# ISP_CSI2C_REGS1 register map
Vendor: Texas Instruments
Peripheral module from a debugger description file (folder omap36xx).
Registers are 32-bit, access per field, reset 0x0 unless marked. A register's access mark holds for its fields unless they carry their own. Offsets are as the file gives them; lines under a group give offsets from that group; [hi:lo] are bit positions; {n}, {i} and the like mark numbered series; 'fields as' and 'values as' point back to an identical list; <NAME> marks a mode.

## ISP_CSI2C_REGS1
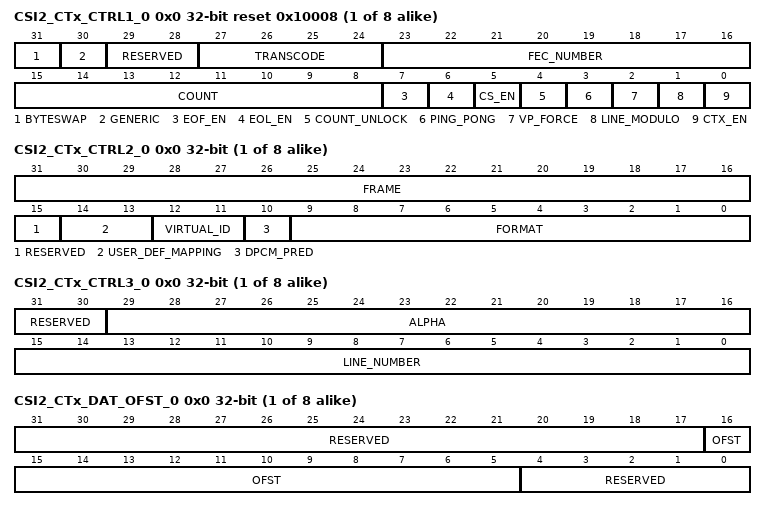
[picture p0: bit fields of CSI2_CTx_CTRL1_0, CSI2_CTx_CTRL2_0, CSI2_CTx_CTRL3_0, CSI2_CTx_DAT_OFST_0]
{0x0+0x20*i} CSI2_CTx_CTRL1_{i} reset 0x10008 (i=0..7) — CONTROL REGISTER - Context This register controls the Context. This register is shadowed: modifications are taken into account after the next FSC sync code.
  [31] BYTESWAP rw — Allows swapping bytes two by two in the payload data.It doesn't affect - short packets- long packet header or footers- CRC calculationThe purpose is to by swap data send to the Interconnect port and/or video port
    0=Disabled; 1=Enabled
  [30] GENERIC rw — Enables the generic mode.
    0=Disabled.Data is received according to CSI2_CTX_CTRL1.FORMAT andthe long packet code transmitted in the MIPI stream is used; 1=Enabled.Data is received according to CSI2_CTX_CTRL1.FORMAT andthe long packet code transmitted in the MIPI stream is ignored
  [29:28] RESERVED ro — Write 0s for future compatibility. Read returns 0.
  [27:24] TRANSCODE rw — Enables image transcoding.When this features is enabled:- the data format from the camera is defined by the FORMAT register- the format after transcode is defined by the TRANSCODE register. The memory storage / video port formats is defined by the TRANSCODE register
    0=Feature disabled; 1=Outputs DPCM compressed RAW10 data.After compression, pixels are coded on 8 bits.Data in memory is organized as regular RAW8 data; 2=Outputs DPCM compressed RAW12 data.After compression, pixels are coded on 8 bits.Data in memory is organized as regular RAW8 data; 3=Outputs ALAW compressed RAW10 data.After compression, pixels are coded on 8 bits.Data in memory is organized as regular RAW8 data; 4=Outputs uncompressed RAW8 data.Data in memory is organized as regular RAW8 data; 5=Outputs uncompressed RAW10 data.Data in memory is organized as regular RAW10+EXP16 data; 6=Outputs uncompressed RAW10 data.Data in memory is organized as regular packed RAW10 data; 7=Outputs uncompressed RAW12 data.Data in memory is organized as regular RAW12+EXP16 data; 8=Outputs uncompressed RAW12 data.Data in memory is organized as regular packed RAW12 data; 9=Outputs uncompressed RAW14 data
  [23:16] FEC_NUMBER rw — Number of FEC to receive between using swap of CSI2_CTX_DAT_PING_ADDR and CSI2_CTX_DAT_PONG_ADDR for the calculation of the address in memory. (shall be used only in interlace mode, otherwise set to '1')
  [15:8] COUNT rw — Sets the number of frame to acquire. Once the frame acquisition starts, the COUNT value is decremented after every frame. When COUNT reaches 0, the FRAME_NUMBER_IRQ interrupt is triggered and CTX_EN is set to '0'. Writes to this bit field are controlled by the COUNT_UNLOCK bit. During the same Interconnect write access , the bit-field COUNT_UNLOCK shall be written in addition to COUNT bit-field in order to change the COUNT value. COUNT can be overwritten dynamically with a new count value.' 0: Infinite number of frames (no count).1: 1 frame to acquire...255: 255 frames to acquire.
  [7] EOF_EN rw — Indicates if the end of frame signal shall be asserted at the end of the line.
    0=EOF_EN_0_r (The end of frame signal is not asserted at the end of each frame.); 1=EOF_EN_1_r (The end of frame signal is asserted at the end of each frame.)
  [6] EOL_EN rw — Indicates if the end of line signal shall be asserted at the end of the line.
    0=EOL_EN_0_r (The end of line signal is not asserted at the end of each frame.); 1=EOL_EN_1_r (The end of line signal is asserted at the end of each frame.)
  [5] CS_EN rw — Enables the checksum check for the received payload (long packet only).
    0=Disabled; 1=Enabled
  [4] COUNT_UNLOCK wo — Unlock writes to the COUNT bit field.
    0=COUNT_UNLOCK_0_w (COUNT bit field is locked. Writes have no effect); 1=COUNT_UNLOCK_1_w (COUNT bit field is unlocked. Writes are possible.)
  [3] PING_PONG ro — Indicates whether the PING or PONG destination address (CSI2_CTX_DAT_PING_ADDR or CSI2_CTX_DAT_PONG_ADDR) was used to write the last frame.This bit field toggles after every FEC_NUMBER FEC sync code received for the current context.
    0=PING_PONG_0_r (PING buffer); 1=PING_PONG_1_r (PONG buffer)
  [2] VP_FORCE rw — Forces sending of the data to both VPORT and Interconnect.Only applies to formats that existing in 2 versions:- one sending data to Interconnect port only- one sending data to VPORTonly (tagged with the +VP extension) The format version sending data only to Interconnect should be choosen.
    0=Disabled; 1=Enabled
  [1] LINE_MODULO rw — Line modulo configuration
    0=CSI2_CTX_CTRL3.LINE_NUMBER is used once per frame for the generation of the LINE_NUMBER_IRQ; 1=CSI2_CTX_CTRL3.LINE_NUMBER is used as a modulo number for the generation of the LINE_NUMBER_IRQ (multiple times the interrupt can be generated for each frame)
  [0] CTX_EN rw — Enables the Context
    0=Disabled; 1=Enabled
{0x0+0x20*i} CSI2_CTx_CTRL2_{i} (i=0..7) — CONTROL REGISTER - Context This register controls the Context. This register is shadowed: modifications are taken into account after the next FSC sync code (except for VIRTUAL_ID and FORMAT fields). The change of VIRTUIAL_ID and FORMAT has to occur only when the context is disabled (CSI2_CTX_CTRL1.CTX_EN).
  [31:16] FRAME ro — Frame number received
  [15] RESERVED ro — Write 0s for future compatibility. Read returns 0.
  [14:13] USER_DEF_MAPPING rw — Selects the pixel format of USER_DEFINED in FORMAT
    0=RAW6; 1=RAW7; 2=RAW8 (not valid if FORMAT is USER_DEFINED_8_BIT_DATA_TYPE_x_EXP8 with x from 1 to 8)
  [12:11] VIRTUAL_ID rw — Virtual channel ID
    {v}=Virtual Channel ID {v} (v=0..3)
  [10] DPCM_PRED rw — Selects the DPCM predictor.
    0=The advanced predictor is used.Not supported for 10 - 8 - 10 algorithm.Performance limited to 1 pixel/cycle; 1=The simple predictor is used
  [9:0] FORMAT rw — Data format selection.
    0=OTHERS (except NULL and BLANKING packets); 18=Embedded 8-bit non-image data (e.g. JPEG); 24=YUV420 8bit; 25=YUV420 10bit; 26=YUV420 8bit legacy; 28=YUV420 8bit + CSPS; 29=YUV420 10bit + CSPS; 30=YUV422 8bit; 31=YUV422 10bit; 34=RGB565; 36=RGB888; 40=RAW6; 41=RAW7; 42=RAW8; 43=RAW10; 44=RAW12; 45=RAW14; 51=RGB666 + EXP32_24; {v}=USER_DEFINED_8_BIT_DATA_TYPE_{v-63} (v=64..71); 104=RAW6 + EXP8; 105=RAW7 + EXP8; {v}=USER_DEFINED_8_BIT_DATA_TYPE_{v-127} + EXP8 (v=128..135); 158=YUV422 8bit + VP; 160=RGB444 + EXP16; 161=RGB555 + EXP16; 171=RAW10 + EXP16; 172=RAW12 + EXP16; 173=RAW14 + EXP16; 222=Same as YUV422 8bit + VP but datais send as 16-bit wide words to video port.Could be used together with the GENERIC and BYTESWAP features; 227=RGB666 + EXP32; 228=RGB888 + EXP32; 232=RAW6 + DPCM10 + VP; 0x12A=RAW8 + VP; 0x12C=RAW12 + VP; 0x12D=RAW14 + VP; 0x12F=RAW10 + VP; 0x140=USER_DEFINED_8_BIT_DATA_TYPE_1_DPCM12_VP; 0x141=USER_DEFINED_8_BIT_DATA_TYPE_2_DPCM12_VP; 0x142=USER_DEFINED_8_BIT_DATA_TYPE_3_DPCM12_VP; 0x143=USER_DEFINED_8_BIT_DATA_TYPE_4_DPCM12_VP; 0x144=USER_DEFINED_8_BIT_DATA_TYPE_5_DPCM12_VP; 0x145=USER_DEFINED_8_BIT_DATA_TYPE_6_DPCM12_VP; 0x146=USER_DEFINED_8_BIT_DATA_TYPE_7_DPCM12_VP; 0x147=USER_DEFINED_8_BIT_DATA_TYPE_8_DPCM12_VP; 0x1C0=USER_DEFINED_8_BIT_DATA_TYPE_1_DPCM12_EXP16; 0x1C1=USER_DEFINED_8_BIT_DATA_TYPE_2_DPCM12_EXP16; 0x1C2=USER_DEFINED_8_BIT_DATA_TYPE_3_DPCM12_EXP16; 0x1C3=USER_DEFINED_8_BIT_DATA_TYPE_4_DPCM12_EXP16; 0x1C4=USER_DEFINED_8_BIT_DATA_TYPE_5_DPCM12_EXP16; 0x1C5=USER_DEFINED_8_BIT_DATA_TYPE_6_DPCM12_EXP16; 0x1C6=USER_DEFINED_8_BIT_DATA_TYPE_7_DPCM12_EXP16; 0x1C7=USER_DEFINED_8_BIT_DATA_TYPE_8_DPCM12_EXP16; 0x229=RAW7 + DPCM10 + EXP16; 0x2A8=RAW6 + DPCM10 + EXP16; 0x2AA=RAW8 + DPCM10 + EXP16; 0x2C0=USER_DEFINED_8_BIT_DATA_TYPE_1 + DPCM10 + EXP16; 0x2C1=USER_DEFINED_8_BIT_DATA_TYPE_2 + DPCM10 + EXP16; 0x2C2=USER_DEFINED_8_BIT_DATA_TYPE_3 + DPCM10 + EXP16; 0x2C3=USER_DEFINED_8_BIT_DATA_TYPE_4 + DPCM10 + EXP16; 0x2C4=USER_DEFINED_8_BIT_DATA_TYPE_5 + DPCM10 + EXP16; 0x2C5=USER_DEFINED_8_BIT_DATA_TYPE_6 + DPCM10 + EXP16; 0x2C6=USER_DEFINED_8_BIT_DATA_TYPE_7 + DPCM10 + EXP16; 0x2C7=USER_DEFINED_8_BIT_DATA_TYPE_8 + DPCM10 + EXP16; 0x329=RAW7 + DPCM10 + VP; 0x32A=RAW8 + DPCM10 + VP; 0x340=USER_DEFINED_8_BIT_DATA_TYPE_1 + DPCM10 + VP; 0x341=USER_DEFINED_8_BIT_DATA_TYPE_2 + DPCM10 + VP; 0x342=USER_DEFINED_8_BIT_DATA_TYPE_3 + DPCM10 + VP; 0x343=USER_DEFINED_8_BIT_DATA_TYPE_4 + DPCM10 + VP; 0x344=USER_DEFINED_8_BIT_DATA_TYPE_5 + DPCM10 + VP; 0x345=USER_DEFINED_8_BIT_DATA_TYPE_6 + DPCM10 + VP; 0x346=USER_DEFINED_8_BIT_DATA_TYPE_7 + DPCM10 + VP; 0x347=USER_DEFINED_8_BIT_DATA_TYPE_8 + DPCM10 + VP; 0x368=RAW6 DPCM12 + VP; 0x369=RAW7 DPCM12 + EXP16; 0x36A=RAW8 DPCM12 + EXP16; 0x3A8=RAW6 DPCM12 + EXP16; 0x3A9=RAW7 DPCM12 + VP; 0x3AA=RAW8 DPCM12 + VP
{0x0+0x20*i} CSI2_CTx_CTRL3_{i} (i=0..7) — CONTROL REGISTER - Context This register controls the Context. This register is shadowed: modifications are taken into account after the next FSC sync code.
  [31:30] RESERVED ro — Write 0s for future compatibility. Read returns 0.
  [29:16] ALPHA rw — Alpha value for RGB888, RGB666 and RBG444.
  [15:0] LINE_NUMBER rw — Line number for the interrupt generation
{0x0+0x20*i} CSI2_CTx_DAT_OFST_{i} (i=0..7) — DATA MEM ADDRESS OFFSET REGISTER - Context This register sets the offset, which is applied on the destination address after each line is written to memory. This register applies for both and . For example, it enables to perform 2D data transfers of the pixel data into a frame buffer. In such case, the pixel data and frame buffer data shall have the same data format. Note that the 5 LSBs are ignored: the offset shall be a multiple of 32 bytes. This register is shadowed: modifications are taken into account after the next FSC sync code. Only full 32-bit values shall be written.
  [31:17] RESERVED ro — Write 0s for future compatibility. Read returns 0.
  [16:5] OFST rw — Line offset programmed in bytes (signed value 2's complement). If OFST = 0, the data is written contiguously in memory. Otherwise, OFST sets the destination offset between the first pixel of the previous line and the first pixel of the current line.
  [4:0] RESERVED ro — Write 0s for future compatibility. Read returns 0.
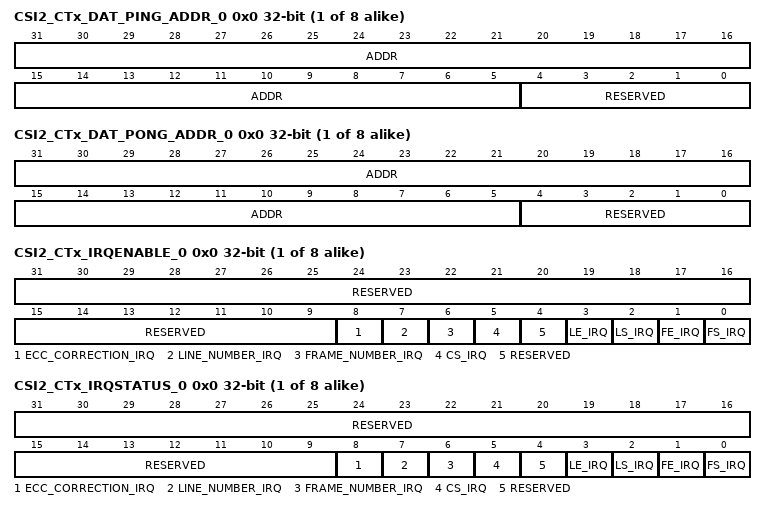
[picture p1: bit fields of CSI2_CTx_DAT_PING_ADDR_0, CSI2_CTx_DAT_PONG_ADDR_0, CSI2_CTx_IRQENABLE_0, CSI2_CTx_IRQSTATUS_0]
{0x0+0x20*i} CSI2_CTx_DAT_PING_ADDR_{i} (i=0..7) — DATA MEM PING ADDRESS REGISTER - Context This register sets the 32-bit memory address where the pixel data are stored. The destination is double buffered: this register sets the PING address. Double buffering is enabled when the addresses and are different. Note that the 5 LSBs are ignored: the address shall be aligned on a 32-byte boundary. This register is shadowed: modifications are taken into account after the next FSC sync code. Only full 32-bit values shall be written.
  [31:5] ADDR rw — 27 most significant bits of the 32-bit address.
  [4:0] RESERVED ro — Write 0s for future compatibility. Read returns 0.
{0x0+0x20*i} CSI2_CTx_DAT_PONG_ADDR_{i} (i=0..7) — DATA MEM PONG ADDRESS REGISTER - Context This register sets the 32-bit memory address where the pixel data are stored. The destination is double buffered: this register sets the PONG address. Double buffering is enabled when the addresses CSI2_CTX_DAT_PING_ADDR and CSI2_CTX_DAT_PONG_ADDR are different. Note that the 5 LSBs are ignored: the address shall be aligned on a 32-byte boundary. This register is shadowed: modifications are taken into account after the next FSC sync code. Only full 32-bit values shall be written.
  fields as CSI2_CTx_DAT_PING_ADDR_0
{0x0+0x20*i} CSI2_CTx_IRQENABLE_{i} (i=0..7) — INTERRUPT ENABLE REGISTER - Context This register regroups all the events related to Context.
  [31:9] RESERVED ro — Write 0s for future compatibility. Read returns 0.
  [8] ECC_CORRECTION_IRQ rw — Context - ECC has been used to correct the only 1-bit error (long packet only).
    0=Event is masked; 1=Event generates an interrupt when it occurs
  [7] LINE_NUMBER_IRQ rw — Context - Line number is reached.
    values as ECC_CORRECTION_IRQ
  [6] FRAME_NUMBER_IRQ rw — Context - Frame counter reached.
    values as ECC_CORRECTION_IRQ
  [5] CS_IRQ rw — Context - Check-Sum of the payload mismatch detection
    values as ECC_CORRECTION_IRQ
  [4] RESERVED ro — Write 0s for future compatibility. Read returns 0.
  [3] LE_IRQ rw — Context - Line end sync code detection.
    values as ECC_CORRECTION_IRQ
  [2] LS_IRQ rw — Context - Line start sync code detection.
    values as ECC_CORRECTION_IRQ
  [1] FE_IRQ rw — Context - Frame end sync code detection.
    values as ECC_CORRECTION_IRQ
  [0] FS_IRQ rw — Context - Frame start sync code detection.
    values as ECC_CORRECTION_IRQ
{0x0+0x20*i} CSI2_CTx_IRQSTATUS_{i} access not given (i=0..7) — INTERRUPT STATUS REGISTER - Context This register regroups all the events related to Context.
  [31:9] RESERVED ro — Write 0s for future compatibility. Read returns 0.
  [8] ECC_CORRECTION_IRQ — Context - ECC has been used to do the correction of the only 1-bit error status (long packet only). (access RW W1toClr)
    0=READS: Event is false.WRITES: Status bit unchanged; 1=READS: Event is true (pending).WRITES: Status bit is reset
  [7] LINE_NUMBER_IRQ — Contexc - Line number reached status. (access RW W1toClr)
    values as ECC_CORRECTION_IRQ
  [6] FRAME_NUMBER_IRQ — Context - Frame counter reached status (access RW W1toClr)
    values as ECC_CORRECTION_IRQ
  [5] CS_IRQ — Context - Check-Sum mismatch status. (access RW W1toClr)
    values as ECC_CORRECTION_IRQ
  [4] RESERVED ro — Write 0s for future compatibility. Read returns 0.
  [3] LE_IRQ — Context - Line end sync code detection status. (access RW W1toClr)
    values as ECC_CORRECTION_IRQ
  [2] LS_IRQ — Context - Line start sync code detection status. (access RW W1toClr)
    values as ECC_CORRECTION_IRQ
  [1] FE_IRQ — Context - Frame end sync code detection status. (access RW W1toClr)
    values as ECC_CORRECTION_IRQ
  [0] FS_IRQ — Context - Frame start sync code detection status. (access RW W1toClr)
    values as ECC_CORRECTION_IRQ
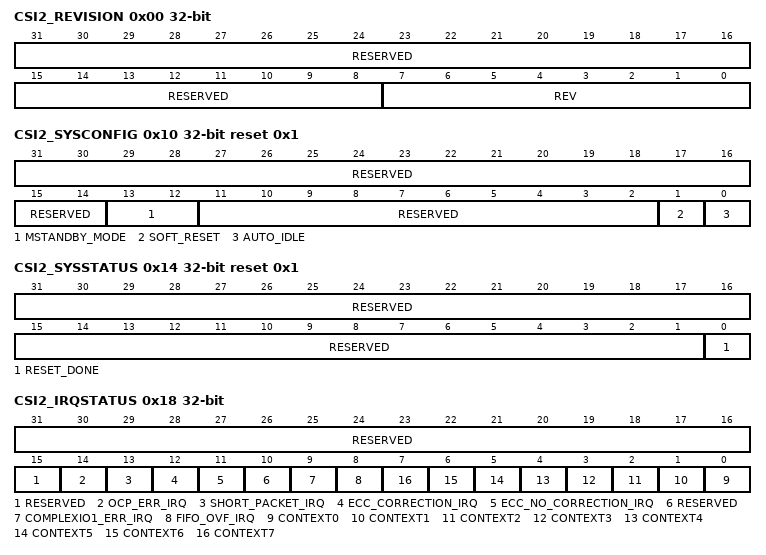
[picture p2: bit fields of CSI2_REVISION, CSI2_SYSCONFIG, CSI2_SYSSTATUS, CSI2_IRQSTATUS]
0x00 CSI2_REVISION ro (reset mask 0xFFFFFF00) — MODULE REVISION This register contains the IP revision code in binary coded digital. For example, 0x01 = revision 0.1 and 0x21 = revision 2.1
  [31:8] RESERVED — Write 0's for future compatibility.Reads returns 0.
  [7:0] REV — IP revision [7:4] Major revision[3:0] Minor revision
0x10 CSI2_SYSCONFIG reset 0x1 — SYSTEM CONFIGURATION REGISTER This register is the Interconnect-socket system configuration register.
  [31:14] RESERVED ro — Write 0s for future compatibility. Read returns 0.
  [13:12] MSTANDBY_MODE rw — Sets the behavior of the master port power management signals.
    0=Force-standby. MStandby is only asserted when the module is disabled.; 1=No-standby. MStandby is never asserted.; 2=Smart-standby: MStandby is asserted based on the activity of the module. The module will try to go to standby during the vertical blanking period.
  [11:2] RESERVED ro — Write 0s for future compatibility. Read returns 0.
  [1] SOFT_RESET rw — Software reset. Set the bit to 1 to trigger a module reset. The bit is automatically reset by the hw. During reads return 0.
    0=Normal mode; 1=The module is reset
  [0] AUTO_IDLE rw — Internal Interconnect gating strategy
    0=Interconnect clock is free-running; 1=Automatic Interconnect clock gating strategy is applied based on the Interconnect interface activity
0x14 CSI2_SYSSTATUS ro reset 0x1 — SYSTEM STATUS REGISTER This register provides status information about the module, excluding the interrupt status register.
  [31:1] RESERVED — Write 0s for future compatibility. Read returns 0..
  [0] RESET_DONE — Internal reset monitoring
    0=RESET_DONE_0_r (Internal module reset is on going.); 1=RESET_DONE_1_r (Reset completed.)
0x18 CSI2_IRQSTATUS access not given — INTERRUPT STATUS REGISTER - All contexts This register associates one bit for each context in order to determine which context has generated the interrupt. The context shall be enabled for events to be generated on that context.If the context is disabled, the interrupt is not generated.
  [31:15] RESERVED ro — Write 0s for future compatibility. Read returns 0.
  [14] OCP_ERR_IRQ — Interconnect Error Interrupt (access RW W1toClr)
    values as CSI2_CTx_IRQSTATUS_0.ECC_CORRECTION_IRQ
  [13] SHORT_PACKET_IRQ — Short packet reception status (other than synch events: Line Start, Line End, Frame Start, and Frame End: data type between 0x8 and x0F only shall be considered). (access RW W1toClr)
    values as CSI2_CTx_IRQSTATUS_0.ECC_CORRECTION_IRQ
  [12] ECC_CORRECTION_IRQ — ECC has been used to do the correction of the only 1-bit error status (short packet only). (access RW W1toClr)
    values as CSI2_CTx_IRQSTATUS_0.ECC_CORRECTION_IRQ
  [11] ECC_NO_CORRECTION_IRQ — ECC error status (short and long packets). No correction of the header because of more than 1-bit error. (access RW W1toClr)
    values as CSI2_CTx_IRQSTATUS_0.ECC_CORRECTION_IRQ
  [10] RESERVED ro — Write 0s for future compatibility. Read returns 0.
  [9] COMPLEXIO1_ERR_IRQ ro — Error signaling from Complex I/O #1: status of the PHY errors received from Complex I/O #1 (events are defined inCSI2_COMPLEXIO1_IRQSTATUS for the first complex I/O).
    0=COMPLEXIO1_ERR_IRQ_0_r (READS: Event is false.); 1=COMPLEXIO1_ERR_IRQ_1_r (READS: Event is true (pending).)
  [8] FIFO_OVF_IRQ — FIFO overflow error status. (access RW W1toClr)
    values as CSI2_CTx_IRQSTATUS_0.ECC_CORRECTION_IRQ
  [n] CONTEXT{n} ro (n=0..7)
    0=CONTEXT{n}_0_r (READS: Event is false.); 1=CONTEXT{n}_1_r (READS: Event is true (pending).)
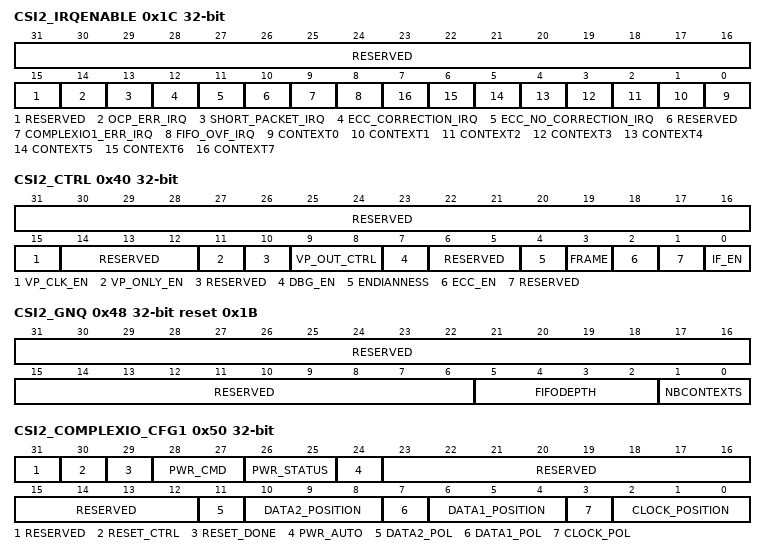
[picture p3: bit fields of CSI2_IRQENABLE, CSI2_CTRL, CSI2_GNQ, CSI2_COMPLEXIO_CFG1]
0x1C CSI2_IRQENABLE — INTERRUPT ENABLE REGISTER - All contexts This register associates one bit for each context in order to enable/disable each context individually.
  [31:15] RESERVED ro — Write 0s for future compatibility. Read returns 0.
  [14] OCP_ERR_IRQ rw — Interconnect Error Interrupt
    values as CSI2_CTx_IRQENABLE_0.ECC_CORRECTION_IRQ
  [13] SHORT_PACKET_IRQ rw — Short packet reception (other than synch events: Line Start, Line End, Frame Start, and Frame End: data type between 0x8 and x0F only shall be considered).
    values as CSI2_CTx_IRQENABLE_0.ECC_CORRECTION_IRQ
  [12] ECC_CORRECTION_IRQ rw — ECC has been used to correct the only 1-bit error (short packet only).
    values as CSI2_CTx_IRQENABLE_0.ECC_CORRECTION_IRQ
  [11] ECC_NO_CORRECTION_IRQ rw — ECC error (short and long packets). No correction of the header because of more than 1-bit error.
    values as CSI2_CTx_IRQENABLE_0.ECC_CORRECTION_IRQ
  [10] RESERVED ro — Write 0s for future compatibility. Read returns 0.
  [9] COMPLEXIO1_ERR_IRQ rw — Error signaling from Complex I/O #1: the interrupt is triggered when any error is received from Complex I/O #1 (events are defined inCSI2_COMPLEXIO1_IRQSTATUS for the first complex I/O).
    values as CSI2_CTx_IRQENABLE_0.ECC_CORRECTION_IRQ
  [8] FIFO_OVF_IRQ rw — FIFO overflow enable
    values as CSI2_CTx_IRQENABLE_0.ECC_CORRECTION_IRQ
  [n] CONTEXT{n} rw (n=0..7)
    values as CSI2_CTx_IRQENABLE_0.ECC_CORRECTION_IRQ
0x40 CSI2_CTRL — GLOBAL CONTROL REGISTER This register controls the CSI2 RECEIVER module. This register shall not be modified dynamically (except IF_EN bit field).
  [31:16] RESERVED ro — Write 0s for future compatibility. Read returns 0.
  [15] VP_CLK_EN rw — VP clock enable.
    0=The VP clock is disabled; 1=The VP clock is enabled
  [14:12] RESERVED rw — Write 0s for future compatibility. Read returns 0.
  [11] VP_ONLY_EN rw — VP only enable.
    0=The VP is enabled and the Interconnect master port is enabled; 1=The VP is enabled and the Interconnect master port is disabled
  [10] RESERVED ro — Write 0s for future compatibility. Read returns 0.
  [9:8] VP_OUT_CTRL rw — Video port output clock control. Sets the video port output clock as a function of the interface clock (OCPCLK).
    1=Division by 2: video port clock = OCPCLK / 2; 2=Division by 3: video port clock = OCPCLK / 3; 3=Division by 4: video port clock = OCPCLK / 4. Note: Software must change the reset value that is not appropriate.
  [7] DBG_EN rw — Enables the debug mode.
    0=Disable; 1=Enable
  [6:5] RESERVED ro — Write 0s for future compatibility. Read returns 0.
  [4] ENDIANNESS rw — Select endianness for YUV422 8 bit and YUV420 legacy formats.
    0=Use native MIPI CSI2 endianness:Little endian for all formats except for YUV422 8b and YUV420 Legacy which a big endian; 1=Store all pixel formats little endian
  [3] FRAME rw — Set the modality in which IF_EN works.
    0=If IF_EN = 0 the interface is disabled immediately; 1=If IF_EN = 1 the interface is disabled after all FEC sync code have been received for the active contexts
  [2] ECC_EN rw — Enables the Error Correction Code check for the received header (short and long packets for all virtual channel ids).
    0=Disabled; 1=Enabled
  [1] RESERVED ro — Write 0s for future compatibility. Read returns 0.
  [0] IF_EN rw — Enables the physical interface to the module.
    0=The interface is disabled. If FRAME = 0, it is disabled immediately. If FRAME = 1, it is disabled when each context has received the FEC sync code.; 1=The interface is enabled immediately, the data acquisition starts on the next FSC sync code. Writing '1' to this register when the current value is '0' has the effect to clear the output FIFO. The pixel data of the following frame will be written in the PING buffer, i.e., the CSI2_CTX_CTRL.PING_PONG bits are reset to '0' as well.
0x44 CSI2_DBG_H wo — DEBUG REGISTER (Header) This register provides a way to debug the CSI2 RECEIVER module with no image sensor connected to the module. The debug mode is enabled by .DBG_EN. Only full 32-bit values shall be written. The register is used to write short packets and header of long packets.
  [31:0] DBG — 32-bit input value.
0x48 CSI2_GNQ ro reset 0x1B — GENERIC PARAMETER REGISTER This register provide a way to read the generic parameters used in the design.
  [31:6] RESERVED — Write 0's for future compatibility.Reads returns 0.
  [5:2] FIFODEPTH — Output FIFO size in multiple of 68 bits.
    2=FIFODEPTH_2_r (8x 68 bits); 3=FIFODEPTH_3_r (16x 68 bits); 4=FIFODEPTH_4_r (32x 68 bits); 5=FIFODEPTH_5_r (64x 68 bits); 6=FIFODEPTH_6_r (128 x 68 bits); 7=FIFODEPTH_7_r (256 x 68 bits)
  [1:0] NBCONTEXTS — Number of contexts supported by the module.
    0=NBCONTEXTS_0_r (1 Context); 1=NBCONTEXTS_1_r (2 Contexts); 2=NBCONTEXTS_2_r (4 Contexts); 3=NBCONTEXTS_3_r (8 Contexts)
0x50 CSI2_COMPLEXIO_CFG1 — PHY configuration register for the PHY associated to the receiver This register contains the lane configuration for the order and position of the lanes (clock and data) and the polarity order for the control of the PHY differential signals in addition to the control bit for the power FSM.
  [31] RESERVED ro — Write 0s for future compatibility. Read returns 0.
  [30] RESET_CTRL rw — Controls the reset of the PHY
    0=PHY reset active; 1=PHY reset de-asserted
  [29] RESET_DONE ro — Internal reset monitoring of the power domain using the PPI byte clock from the PHY
    values as CSI2_SYSSTATUS.RESET_DONE
  [28:27] PWR_CMD rw — Command for power control of the PHY
    0=Command to change to OFF state; 1=Command to change to ON state; 2=Command to change to Ultra Low Power state
  [26:25] PWR_STATUS ro — Status of the power control of the PHY
    0=PWR_STATUS_0_r (PHY in OFF state); 1=PWR_STATUS_1_r (PHY in ON state); 2=PWR_STATUS_2_r (PHY in Ultra Low Power state)
  [24] PWR_AUTO rw — Automatic switch between ULP and ON states based on ULPM signals from PHY
    0=Disable; 1=Enable
  [23:12] RESERVED ro — Write 0s for future compatibility. Read returns 0.
  [11] DATA2_POL rw — +/- differential pin order of DATA lane 2.
    0=+/- pin order; 1=-/+ pin order
  [10:8] DATA2_POSITION rw — Position and order of the DATA lane 2.Note:If the parallel camera sensor and the other camera sensor (CCP2 or CSI2) are connected to the same CSIPHY, the SCM.CONTROL_CAMERAx_PHY_CAMMOD bit must be set for CCP2 or CSI2mode, respectively, (even if only one pair is used as GPI for CPI mode). The corresponding DATAx_POSITION bit must be set to 0x0 for the lane in GPI mode. .
    0=Not used/connected; 1=Data lane 2 is at position 1; 2=Data lane 2 is at position 2; 3=Data lane 2 is at position 3
  [7] DATA1_POL rw — +/- differential pin order of DATA lane 1.
    0=+/- pin order; 1=-/+ pin order
  [6:4] DATA1_POSITION rw — Position and order of the DATA lane 1.The data lane 1 is always present. . Note:If the parallel camera sensor and the other camera sensor (CCP2 or CSI2) are connected to the same CSIPHY, the SCM.CONTROL_CAMERAx_PHY_CAMMOD bit must be set for CCP2 or CSI2mode, respectively, (even if only one pair is used as GPI for CPI mode). The corresponding DATAx_POSITION bit must be set to 0x0 for the lane in GPI mode. . Note: The settings differ when using CSIPHY1/CSIPHY2 and CCP2. See , Camera ISP CSIPHY Initialization for Work With CSI1/CCP2B Receiver. .
    0=Not used/connected; 1=Data lane 1 is at position 1; 2=Data lane 1 is at position 2; 3=Data lane 1 is at position 3
  [3] CLOCK_POL rw — ±differential pin order of CLOCK lane.
    0=± pin order; 1=± pin order
  [2:0] CLOCK_POSITION rw — Position and order of the CLOCK lane. The clock lane is always present.Note: The settings differ when using CSIPHY1/CSIPHY2 and CCP2. See , Camera ISP CSIPHY Initialization for Work With CSI1/CCP2B Receiver. .
    0=Not used/connected; 1=Clock lane is at position 1; 2=Clock lane is at position 2; 3=Clock lane is at position 3; 5=Clock lane is at position 2 (using CSIPHY1) or 1 (using CSIPHY2). This setting is valid for CCP2 receiver mode only.
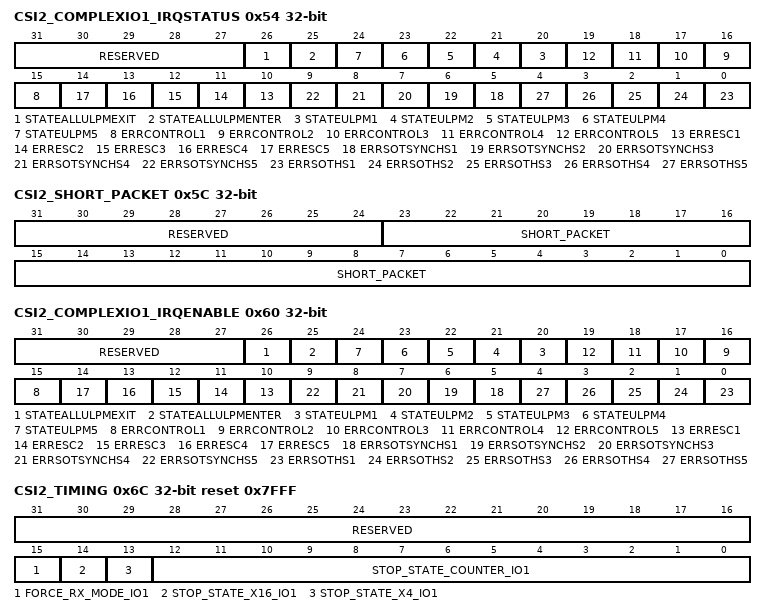
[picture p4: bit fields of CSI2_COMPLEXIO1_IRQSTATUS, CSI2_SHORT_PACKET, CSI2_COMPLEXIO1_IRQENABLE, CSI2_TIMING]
0x54 CSI2_COMPLEXIO1_IRQSTATUS access not given — INTERRUPT STATUS REGISTER - All errors from the associated PHY
  [31:27] RESERVED ro — Write 0s for future compatibility. Read returns 0.
  [26] STATEALLULPMEXIT — At least one of the active lanes has exit the ULPM (access RW W1toClr)
    values as CSI2_CTx_IRQSTATUS_0.ECC_CORRECTION_IRQ
  [25] STATEALLULPMENTER — All active lanes are entering in ULPM. (access RW W1toClr)
    values as CSI2_CTx_IRQSTATUS_0.ECC_CORRECTION_IRQ
  [n+19] STATEULPM{n} (n=1..5) — Lane #{n} in Ultra Low Power Mode (access RW W1toClr)
    values as CSI2_CTx_IRQSTATUS_0.ECC_CORRECTION_IRQ
  [n+14] ERRCONTROL{n} (n=1..5) — Control error for lane #{n} (access RW W1toClr)
    values as CSI2_CTx_IRQSTATUS_0.ECC_CORRECTION_IRQ
  [n+9] ERRESC{n} (n=1..5) — Escape entry error for lane #{n} (access RW W1toClr)
    values as CSI2_CTx_IRQSTATUS_0.ECC_CORRECTION_IRQ
  [n+4] ERRSOTSYNCHS{n} (n=1..5) — Start of transmission sync error for lane #{n} (access RW W1toClr)
    values as CSI2_CTx_IRQSTATUS_0.ECC_CORRECTION_IRQ
  [n-1] ERRSOTHS{n} (n=1..5) — Start of transmission error for lane #{n} (access RW W1toClr)
    values as CSI2_CTx_IRQSTATUS_0.ECC_CORRECTION_IRQ
0x5C CSI2_SHORT_PACKET ro — SHORT PACKET INFORMATION - This register sets the 24-bit DATA_ID + Short Packet Data Field when the data type is between 0x8 and x0F
  [31:24] RESERVED — Write 0s for future compatibility. Read returns 0.
  [23:0] SHORT_PACKET — Short Packet information: DATA ID + DATA FIELD
0x60 CSI2_COMPLEXIO1_IRQENABLE — INTERRUPT ENABLE REGISTER - All errors from associated PHY
  [31:27] RESERVED ro — Write 0s for future compatibility. Read returns 0.
  [26] STATEALLULPMEXIT rw — At least one of the active lanes has exit the ULPM
    values as CSI2_CTx_IRQENABLE_0.ECC_CORRECTION_IRQ
  [25] STATEALLULPMENTER rw — All active lanes are entering in ULPM.
    values as CSI2_CTx_IRQENABLE_0.ECC_CORRECTION_IRQ
  [n+19] STATEULPM{n} rw (n=1..5) — Lane #{n} in Ultra Low Power Mode
    values as CSI2_CTx_IRQENABLE_0.ECC_CORRECTION_IRQ
  [n+14] ERRCONTROL{n} rw (n=1..5) — Control error for lane #{n}
    values as CSI2_CTx_IRQENABLE_0.ECC_CORRECTION_IRQ
  [n+9] ERRESC{n} rw (n=1..5) — Escape entry error for lane #{n}
    values as CSI2_CTx_IRQENABLE_0.ECC_CORRECTION_IRQ
  [n+4] ERRSOTSYNCHS{n} rw (n=1..5) — Start of transmission sync error for lane #{n}
    values as CSI2_CTx_IRQENABLE_0.ECC_CORRECTION_IRQ
  [n-1] ERRSOTHS{n} rw (n=1..5) — Start of transmission error for lane #{n}
    values as CSI2_CTx_IRQENABLE_0.ECC_CORRECTION_IRQ
0x68 CSI2_DBG_P wo — DEBUG REGISTER (Payload) This register provides a way to debug the CSI2 RECEIVER module with no image sensor connected to the module. The debug mode is enabled by .DBG_EN. Only full 32-bit values shall be written. The register is used to write payload of long packets.
  [31:0] DBG — 32-bit input value.
0x6C CSI2_TIMING rw reset 0x7FFF — TIMING REGISTER This register controls the CSI2 RECEIVER module. This register shall not be modified while .IF_EN is set to '1'.It is used to indicate the number of L3 cycles for the Stop State monitoring.
  [31:16] RESERVED — Write 0s for future compatibility. Read returns 0.
  [15] FORCE_RX_MODE_IO1 — Control of ForceRxMode signal
    0=De-assertion of ForceRxMode. The HW reset the bit at the end of the Force RX Mode assertion.The SW can reset the bit in order to stop the assertion of the ForceRXMode signal prior to the completion of the period.; 1=Assertion of ForceRxMode
  [14] STOP_STATE_X16_IO1 — Multiplication factor for the number of L3 cycles defined in STOP_STATE_COUNTER_IO1 bit-field
    0=The number of L3 cycles defined in STOP_STATE _COUNTER_IO1 is multiplied by 1x; 1=The number of L3 cycles defined in STOP_STATE _COUNTER_IO1 is multiplied by 16x
  [13] STOP_STATE_X4_IO1 — Multiplication factor for the number of L3 cycles defined in STOP_STATE_COUNTER_IO1 bit-field
    0=The number of L3 cycles defined in STOP_STATE _COUNTER_IO1 is multiplied by 1x; 1=The number of L3 cycles defined in STOP_STATE _COUNTER_IO1 is multiplied by 4x
  [12:0] STOP_STATE_COUNTER_IO1 — Stop State counter for monitoring. It indicates the number of L3 to monitor for Stop State before de-asserting ForceRxMode (Complex I/O #1).The value is from 0 to 8191.
